# apollo1 register map
Vendor: Ambiq Micro, Inc.; Series: Apollo; File version: 1.0
CPU: CM4 r1p0, little endian, MPU, FPU, 3 interrupt priority bits
Registers are 32-bit, read-write, reset 0x0 unless marked. A register's access mark holds for its fields unless they carry their own. Offsets are from the block's base; [hi:lo] are bit positions; 'fields as' and 'values as' point back to an identical list.

## RSTGEN — MCU Reset Generator
Base 0x40000000
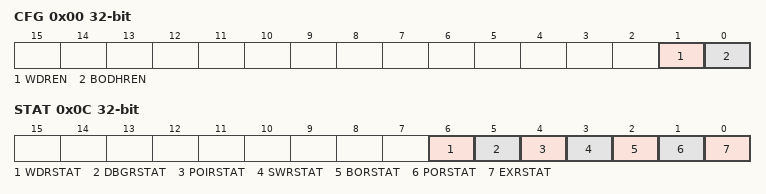
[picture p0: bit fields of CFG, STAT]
0x00 CFG — Configuration Register
  [1] WDREN — Watchdog Timer Reset Enable. NOTE: The WDT module must also be configured for WDT reset.
  [0] BODHREN — Brown out high (2.1v) reset enable.
0x04 SWPOI — Software POI Reset
  [7:0] SWPOIKEY — 0x1B generates a software POI reset.
    27=KEYVALUE (Writing 0x1B key value generates a software POI reset.)
0x08 SWPOR — Software POR Reset
  [7:0] SWPORKEY — 0xD4 generates a software POR reset.
    212=KEYVALUE (Writing 0xD4 key value generates a software POR reset.)
0x0C STAT — Status Register
  [6] WDRSTAT — Reset was initiated by a Watchdog Timer Reset.
  [5] DBGRSTAT — Reset was a initiated by Debugger Reset.
  [4] POIRSTAT — Reset was a initiated by Software POI Reset.
  [3] SWRSTAT — Reset was a initiated by SW POR or AIRCR Reset.
  [2] BORSTAT — Reset was initiated by a Brown-Out Reset.
  [1] PORSTAT — Reset was initiated by a Power-On Reset.
  [0] EXRSTAT — Reset was initiated by an External Reset.
0x10 CLRSTAT — Clear the status register
  [0] CLRSTAT — Writing a 1 to this bit clears all bits in the RST_STAT.
0x200 INTEN — Reset Interrupt register: Enable
  [0] BODH — Enables an interrupt that triggers when VCC is below BODH level.
0x204 INTSTAT — Reset Interrupt register: Status
  fields as INTEN
0x208 INTCLR — Reset Interrupt register: Clear
  fields as INTEN
0x20C INTSET — Reset Interrupt register: Set
  fields as INTEN

## RTC — Real Time Clock
Base 0x40004040
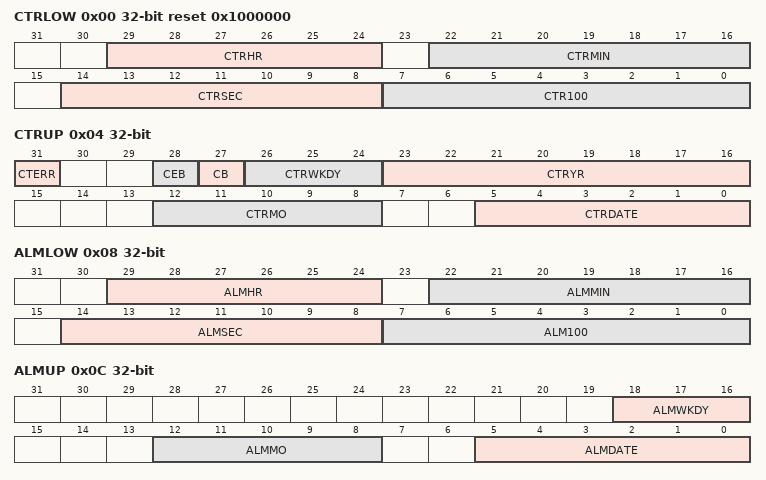
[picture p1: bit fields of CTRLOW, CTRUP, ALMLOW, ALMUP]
0x00 CTRLOW reset 0x1000000 — RTC Counters Lower
  [29:24] CTRHR — Hours Counter
  [22:16] CTRMIN — Minutes Counter
  [14:8] CTRSEC — Seconds Counter
  [7:0] CTR100 — 100ths of a second Counter
0x04 CTRUP — RTC Counters Upper
  [31] CTERR — Counter read error status
    0=NOERR (No read error occurred); 1=RDERR (Read error occurred)
  [28] CEB — Century enable
    0=DIS (Disable the Century bit from changing); 1=EN (Enable the Century bit to change)
  [27] CB — Century
    0=Century is 2000s; 1=1900_2100 (Century is 1900s/2100s)
  [26:24] CTRWKDY — Weekdays Counter
  [23:16] CTRYR — Years Counter
  [12:8] CTRMO — Months Counter
  [5:0] CTRDATE — Date Counter
0x08 ALMLOW — RTC Alarms Lower
  [29:24] ALMHR — Hours Alarm
  [22:16] ALMMIN — Minutes Alarm
  [14:8] ALMSEC — Seconds Alarm
  [7:0] ALM100 — 100ths of a second Alarm
0x0C ALMUP — RTC Alarms Upper
  [18:16] ALMWKDY — Weekdays Alarm
  [12:8] ALMMO — Months Alarm
  [5:0] ALMDATE — Date Alarm
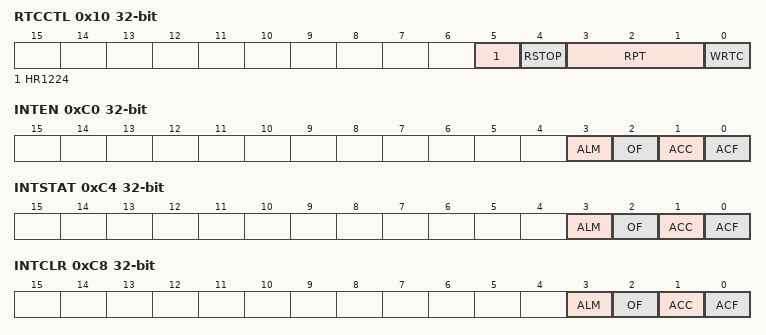
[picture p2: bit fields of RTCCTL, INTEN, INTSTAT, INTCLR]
0x10 RTCCTL — RTC Control Register
  [5] HR1224 — Hours Counter mode
    0=24HR (Hours in 24 hour mode); 1=12HR (Hours in 12 hour mode)
  [4] RSTOP — RTC input clock control
    0=RUN (Allow the RTC input clock to run); 1=STOP (Stop the RTC input clock)
  [3:1] RPT — Alarm repeat interval
    0=DIS (Alarm interrupt disabled); 1=YEAR (Interrupt every year); 2=MONTH (Interrupt every month); 3=WEEK (Interrupt every week); 4=DAY (Interrupt every day); 5=HR (Interrupt every hour); 6=MIN (Interrupt every minute); 7=SEC (Interrupt every second/10th/100th)
  [0] WRTC — Counter write control
    0=DIS (Counter writes are disabled); 1=EN (Counter writes are enabled)
0xC0 INTEN — CLK_GEN Interrupt Register: Enable
  [3] ALM — RTC Alarm interrupt
  [2] OF — XT Oscillator Fail interrupt
  [1] ACC — Autocalibration Complete interrupt
  [0] ACF — Autocalibration Fail interrupt
0xC4 INTSTAT — CLK_GEN Interrupt Register: Status
  fields as INTEN
0xC8 INTCLR — CLK_GEN Interrupt Register: Clear
  fields as INTEN
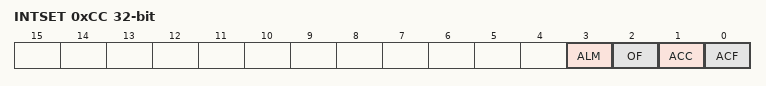
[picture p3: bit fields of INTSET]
0xCC INTSET — CLK_GEN Interrupt Register: Set
  fields as INTEN

## VCOMP — Voltage Comparator
Base 0x4000C000
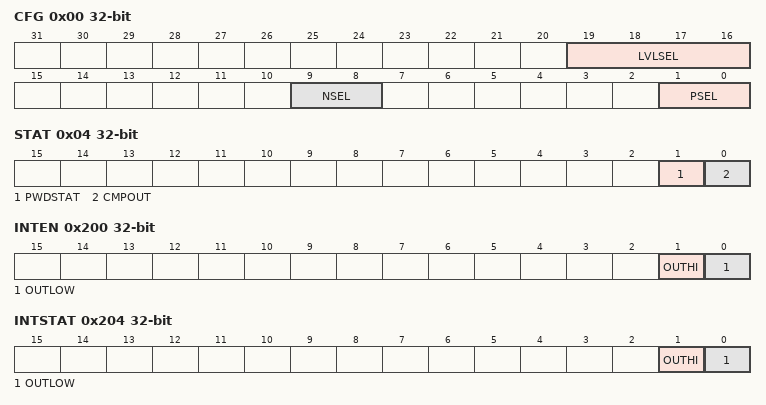
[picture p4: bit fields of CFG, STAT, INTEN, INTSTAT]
0x00 CFG — Configuration Register
  [19:16] LVLSEL — When the reference input NSEL is set to NSEL_DAC, this bitfield selects the voltage level for the negative input to the comparator.
    0=0P58V (Set Reference input to 0.58 Volts.); 1=0P77V (Set Reference input to 0.77 Volts.); 2=0P97V (Set Reference input to 0.97 Volts.); 3=1P16V (Set Reference input to 1.16 Volts.); 4=1P35V (Set Reference input to 1.35 Volts.); 5=1P55V (Set Reference input to 1.55 Volts.); 6=1P74V (Set Reference input to 1.74 Volts.); 7=1P93V (Set Reference input to 1.93 Volts.); 8=2P13V (Set Reference input to 2.13 Volts.); 9=2P32V (Set Reference input to 2.32 Volts.); 10=2P51V (Set Reference input to 2.51 Volts.); 11=2P71V (Set Reference input to 2.71 Volts.); 12=2P90V (Set Reference input to 2.90 Volts.); 13=3P09V (Set Reference input to 3.09 Volts.); 14=3P29V (Set Reference input to 3.29 Volts.); 15=3P48V (Set Reference input to 3.48 Volts.)
  [9:8] NSEL — This bitfield selects the negative input to the comparator.
    0=VREFEXT1 (Use external reference 1 for reference input.); 1=VREFEXT2 (Use external reference 2 for reference input.); 3=VREFEXT3 (Use external reference 3 for reference input.)
  [1:0] PSEL — This bitfield selects the positive input to the comparator.
    0=VDDADJ (Use VDDADJ for the positive input.); 1=VTEMP (Use the temperature sensor output for the positive input.); 2=VEXT1 (Use external voltage 1 for positive input.); 3=VEXT2 (Use external voltage 1 for positive input.)
0x04 STAT — Status Register
  [1] PWDSTAT — This bit indicates the power down state of the voltage comparator.
    1=POWERED_DOWN (The voltage comparator is powered down.)
  [0] CMPOUT — This bit is 1 if the positive input of the comparator is greater than the negative input.
    0=VOUT_LOW (The negative input of the comparator is greater than the positive input.); 1=VOUT_HIGH (The positive input of the comparator is greater than the negative input.)
0x08 PWDKEY — Key Register for Powering Down the Voltage Comparator
  [31:0] PWDKEY — Key register value.
    55=Key
0x200 INTEN — Voltage Comparator Interrupt registers: Enable
  [1] OUTHI — This bit is the vcompout high interrupt.
  [0] OUTLOW — This bit is the vcompout low interrupt.
0x204 INTSTAT — Voltage Comparator Interrupt registers: Status
  fields as INTEN
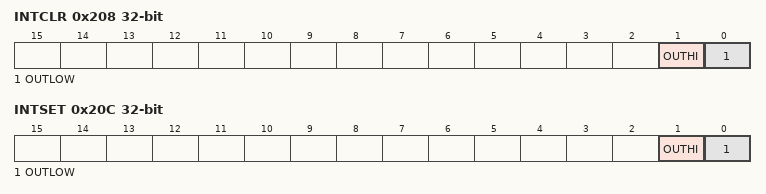
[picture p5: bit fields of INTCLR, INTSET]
0x208 INTCLR — Voltage Comparator Interrupt registers: Clear
  fields as INTEN
0x20C INTSET — Voltage Comparator Interrupt registers: Set
  fields as INTEN

## WDT — Watchdog Timer
Base 0x40024000
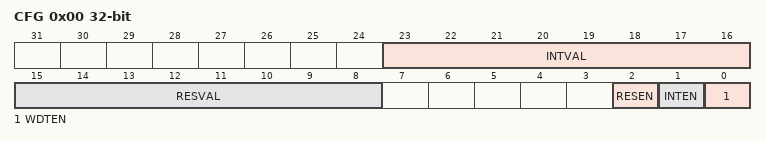
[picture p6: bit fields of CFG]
0x00 CFG — Configuration Register
  [23:16] INTVAL — This bitfield is the compare value for counter bits 7:0 to generate a watchdog interrupt.
  [15:8] RESVAL — This bitfield is the compare value for counter bits 7:0 to generate a watchdog reset.
  [2] RESEN — This bitfield enables the WDT reset.
  [1] INTEN — This bitfield enables the WDT interrupt. Note : This bit must be set before the interrupt status bit will reflect a watchdog timer expiration. The IER interrupt register must also be enabled for a WDT interrupt to be sent to the NVIC.
  [0] WDTEN — This bitfield enables the WDT.
0x04 RSTRT — Restart the watchdog timer
  [7:0] RSTRT — Writing 0xB2 to WDTRSTRT restarts the watchdog timer.
    178=KEYVALUE (This is the key value to write to WDTRSTRT to restart the WDT.)
0x08 LOCK — Locks the WDT
  [7:0] LOCK — Writing 0x3A locks the watchdog timer. Once locked, the WDTCFG reg cannot be written and WDTEN is set.
    58=KEYVALUE (This is the key value to write to WDTLOCK to lock the WDT.)
0x200 INTEN — WDT Interrupt register: Enable
  [0] WDTINT — Watchdog Timer Interrupt.
0x204 INTSTAT — WDT Interrupt register: Status
  [0] WDTINT — Watchdog Timer Interrupt.
0x208 INTCLR — WDT Interrupt register: Clear
  [0] WDTINT — Watchdog Timer Interrupt.
0x20C INTSET — WDT Interrupt register: Set
  [0] WDTINT — Watchdog Timer Interrupt.
